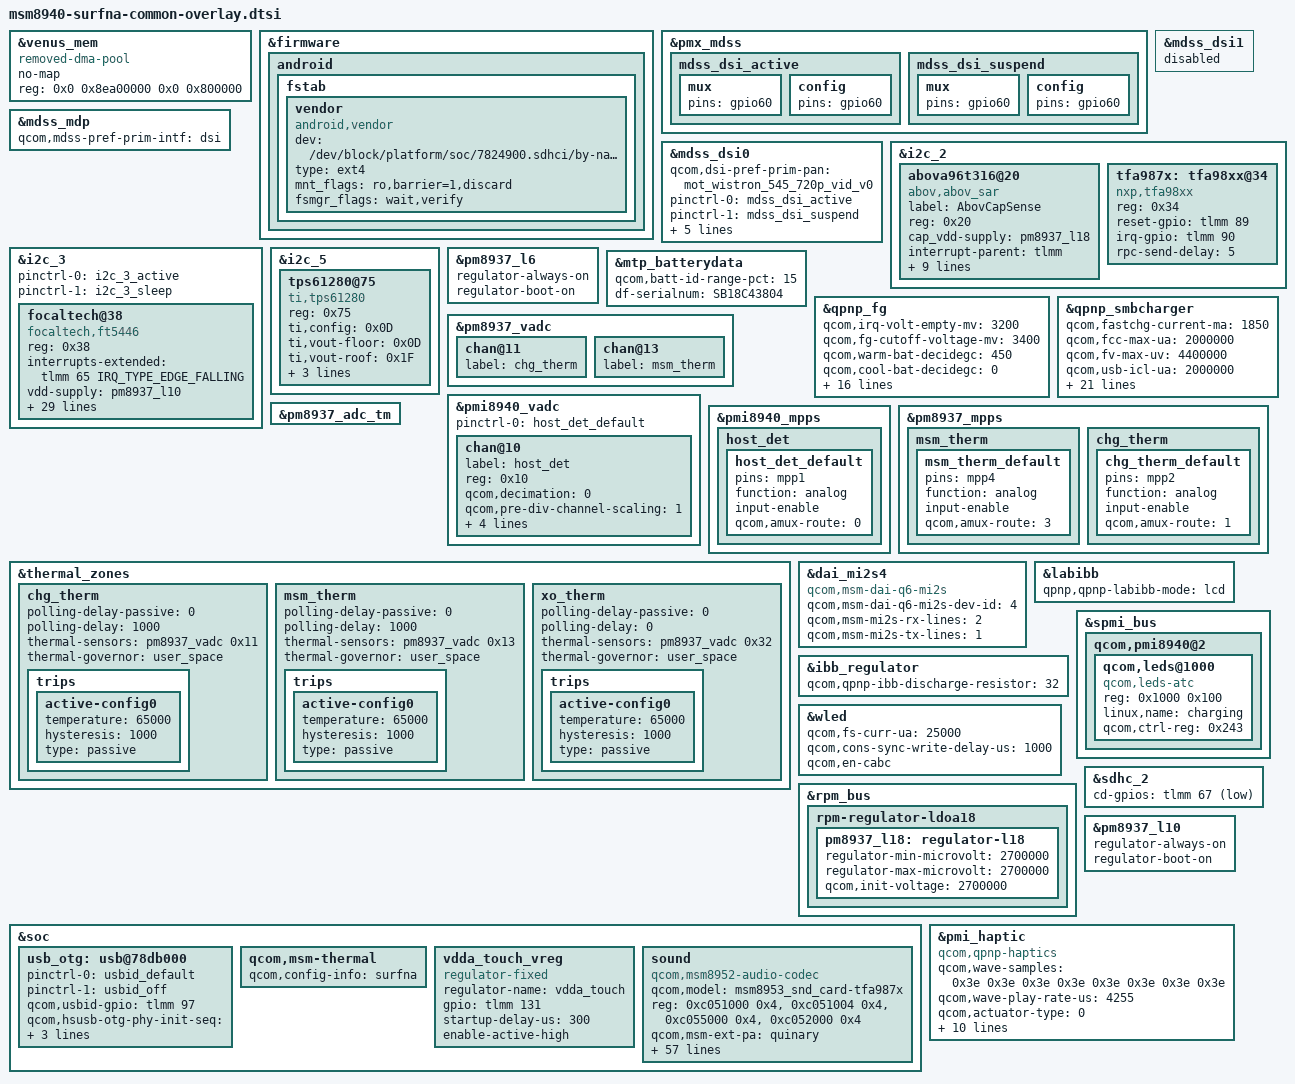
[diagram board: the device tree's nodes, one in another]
/* Copyright (c) 2018, Motorola Mobility Inc. All rights reserved.
 *
 * This program is free software; you can redistribute it and/or modify
 * it under the terms of the GNU General Public License version 2 and
 * only version 2 as published by the Free Software Foundation.
 *
 * This program is distributed in the hope that it will be useful,
 * but WITHOUT ANY WARRANTY; without even the implied warranty of
 * MERCHANTABILITY or FITNESS FOR A PARTICULAR PURPOSE.  See the
 * GNU General Public License for more details.
 */
#include "msm8940-moto-common-overlay.dtsi"
#include "msm8940-surfna-pinctrl-overlay.dtsi"
#include "msm8940-camera-sensor-surfna-overlay.dtsi"
#include "dsi-panel-mot-ofilm-545-720p-vid.dtsi"
#include "dsi-panel-mot-wistron_545_720p-video.dtsi"
#include "dsi-panel-mot-hlt-545-720p-vid.dtsi"
#include "dsi-panel-mot-djn_545_720p-video.dtsi"
#include <dt-bindings/interrupt-controller/irq.h>

&venus_mem {
	compatible = "removed-dma-pool";
	no-map;
	reg = <0x0 0x8ea00000 0x0 0x800000>;
};

&firmware {
	android {
		fstab {
			vendor {
				compatible = "android,vendor";
				dev = "/dev/block/platform/soc/7824900.sdhci/by-name/vendor";
				type = "ext4";
				mnt_flags = "ro,barrier=1,discard";
				fsmgr_flags = "wait,verify";
				status = "ok";
			};
		};
	};
};

&pmx_mdss {
	mdss_dsi_active {
		mux {
			pins = "gpio60";
		};

		config {
			pins = "gpio60";
		};
	};

	mdss_dsi_suspend {
		mux {
			pins = "gpio60";
		};

		config {
			pins = "gpio60";
		};
	};
};

&mdss_mdp {
	qcom,mdss-pref-prim-intf = "dsi";
};

&mdss_dsi0 {
	qcom,dsi-pref-prim-pan = <&mot_wistron_545_720p_vid_v0>;

	pinctrl-names = "mdss_default", "mdss_sleep";
	pinctrl-0 = <&mdss_dsi_active>;
	pinctrl-1 = <&mdss_dsi_suspend>;

	vddio_disp-supply = <&pm8937_l6>;
	vsp_disp-supply = <&lab_regulator>;
	vsn_disp-supply = <&ibb_regulator>;
	qcom,regulator-ldo-mode;
	qcom,platform-reset-gpio = <&tlmm 60 0>;
};

&mdss_dsi1 {
	status = "disabled";
};

&i2c_2 {
	status = "ok";
	abova96t316@20 {
		label = "AbovCapSense";
		compatible = "abov,abov_sar";
		reg = <0x20>;
		cap_vdd-supply = <&pm8937_l18>;
		//cap_svdd-supply = <&pm660_l14>;
		interrupt-parent = <&tlmm>;
		interrupts = <44 0x2008>;
		gpios = <&tlmm 44 0x2008>; /* IRQ */
		pinctrl-names = "default";
		pinctrl-0 = <&abov_int_default>;
		cap,use_channel = <0x0f>;
		cap,use_channel_top = <0x01>;
		cap,use_channel_bottom = <0x00>;
		cap,scan_period = <0x02>;
		reg_array_len = <3>;
		reg_array_val = <0x07 0x00 0x08 0x07 0xFB 0x01>;
	};

	/delete-node/ adv7533@39;
	/delete-node/ pericom-type-c@1d;

	tfa987x:tfa98xx@34 {
		compatible = "nxp,tfa98xx";
		reg = <0x34>;
		reset-gpio = <&tlmm 89 0>;
		irq-gpio = <&tlmm 90 0>;
		rpc-send-delay = <5>;
		status = "ok";
	};
};

&i2c_3 {
	status = "ok";
	/* clock-frequency = <400000>; */
	pinctrl-names = "i2c_active", "i2c_sleep";
	pinctrl-0 = <&i2c_3_active>;
	pinctrl-1 = <&i2c_3_sleep>;
	focaltech@38 {
		compatible = "focaltech,ft5446", "focaltech,mmi";
		reg = <0x38>;
		interrupts-extended = <&tlmm 65 IRQ_TYPE_EDGE_FALLING>;
                vdd-supply = <&pm8937_l10>;
		vcc_i2c-supply = <&pm8937_l5>;
		pinctrl-names = "pmx_ts_active","pmx_ts_suspend","pmx_ts_release";
		pinctrl-0 = <&ts_int_active &ts_reset_active>;
		pinctrl-1 = <&ts_int_suspend &ts_reset_suspend>;
		pinctrl-2 = <&ts_release>;
		focaltech,name = "ft5446";
		focaltech,family-id = <0x22>;
		focaltech,reset-gpio = <&tlmm 64 0x01>;
		focaltech,irq-gpio = <&tlmm 65 0x02>;
		focaltech,display-coords = <0 0 720 1440>;
		focaltech,max-touch-number = <10>;
		focaltech,no-force-update;
		focaltech,i2c-pull-up;
		focaltech,group-id = <1>;
		focaltech,hard-reset-delay-ms = <20>;
		focaltech,soft-reset-delay-ms = <200>;
		focaltech,num-max-touches = <10>;
		focaltech,fw-delay-aa-ms = <30>;
		focaltech,fw-delay-55-ms = <30>;
		focaltech,fw-upgrade-id1 = <0x79>;
		focaltech,fw-upgrade-id2 = <0x08>;
		focaltech,fw-delay-readid-ms = <10>;
		focaltech,fw-delay-era-flsh-ms = <2000>;
                focaltech,fw-update-mmi;
		focaltech,fw-auto-cal;
		focaltech,resume-in-workqueue;
		focaltech,ignore-id-check;
		touchpanel,use_dev_path;
		touchpanel,rst-gpio = <&tlmm 64 0x01>;
		touchpanel,irq-gpio = <&tlmm 65 0x02>;
	};

};

&i2c_5 {
	status = "ok";
	tps61280@75 {
		compatible = "ti,tps61280";
		status = "okay";
		reg = <0x75>;
		ti,config = <0x0D>;
		ti,vout-floor = <0x0D>;
		ti,vout-roof = <0x1F>;
		ti,ilim = <0x0F>;
		ti,en-gpio = <&tlmm 96 0x00>;
		pinctrl-names = "default";
		pinctrl-0 = <&tps61280_en_default>;
	};
};

&pm8937_l6 {
	regulator-always-on;
	regulator-boot-on;
};

&mtp_batterydata {
	qcom,batt-id-range-pct = <15>;
        df-serialnum = "SB18C43804";
        #include "batterydata-ke40-atl.dtsi"
        #include "batterydata-KE40_Sunwoda-4V4-2820mah.dtsi"
};


&qpnp_fg {
	qcom,irq-volt-empty-mv = <3200>;
	qcom,fg-cutoff-voltage-mv = <3400>;

	status = "okay";
	qcom,warm-bat-decidegc = <450>;
	qcom,cool-bat-decidegc = <0>;
	qcom,hot-bat-decidegc = <600>;
	qcom,cold-bat-decidegc = <(-200)>;
	/delete-property/ qcom,ext-sense-type; /* External Sense Resistor */
	qcom,thermal-coefficients = [DA 86 F0 50 08 3C];
	qcom,resume-soc = <99>;
	qcom,bcl-lm-threshold-ma = <126>;
	qcom,bcl-mh-threshold-ma = <400>;
	qcom,fg-iterm-ma = <150>;
        qcom,fg-chg-iterm-ma = <58>;
	qcom,fg-vbat-estimate-diff-mv = <1000>;
	qcom,fg-delta-soc = <1>;
	qcom,fg-max-soc = <100>;
	qcom,fg-min-soc = <0>;
	qcom,fg-cc-cv-threshold-mv = <4390>;
	qcom,battery-data = <&mtp_batterydata>;

	qcom,cl-vbat-est-thr-uv = <300000>;
	qcom,fg-force-restart-enable;
	/delete-property/ qcom,support_multi_coefficients;
};

&qpnp_smbcharger {
	qcom,fastchg-current-ma = <1850>;
	qcom,fcc-max-ua = <2000000>;
	qcom,fv-max-uv = <4400000>;
	qcom,usb-icl-ua = <2000000>;
	qcom,battery-data = <&mtp_batterydata>;
	qcom,chg-thermal-mitigation = <2000>,
                                <1850>,
				<1600>,
				<1200>,
				<1000>,
				<700>,
				<400>;
	qcom,enable-charging-limit;
	qcom,upper-limit-capacity = <75>;
	qcom,lower-limit-capacity = <60>;
	qcom,mmi-disable-hvdcp;
	dpdm-supply = <&usb_otg>;
	//qcom,chg-led-sw-controls;
	//qcom,chg-led-support;

	/delete-property/ qcom,dc-thermal-mitigation;
        qcom,parallel-charge-current-map = <2000 2000 0>,
                                        <1850 1850 0>,
					<1600 1600 0>,
					<1200 1200 0>,
					<1000 1000 0>,
					<700 700 0>,
					<400 400 0>;
	qcom,stepchg-voltage-mv = <4200>;
	qcom,stepchg-current-ma = <1850>;
	qcom,stepchg-taper-ma = <1850>;
	qcom,stepchg-iterm-ma = <58>;
	/delete-property/ qcom,enable-hvdcp-9v;
	qcom,weak-charger-check-enable;
	qcom,temp-warm-current-ma = <1455>;
	qcom,temp-cool-current-ma = <582>;
	qcom,temp-slightly-cool-current-ma = <582>;
	qcom,slightly-cool-temp-c = <15>;
        qcom,cold-temp-c = <(-14)>;
};

&pm8937_vadc {
	chan@11 {
		label = "chg_therm";
        };

	chan@13 {
		label = "msm_therm";
	};
};

&pmi8940_vadc {
        pinctrl-names = "default";
        pinctrl-0 = <&host_det_default>;

	chan@10 {
		label = "host_det";
		reg = <0x10>;
		qcom,decimation = <0>;
		qcom,pre-div-channel-scaling = <1>;
		qcom,calibration-type = "absolute";
		qcom,scale-function = <0>;
		qcom,hw-settle-time = <1>;
		qcom,fast-avg-setup = <2>;
	};
};

&pmi8940_mpps {
        host_det {
               host_det_default: host_det_default {
                     pins = "mpp1";
                     function = "analog";
                     input-enable;
                     qcom,amux-route = <0>;
               };
        };
};


&pm8937_adc_tm {
        #thermal-sensor-cells = <1>;
};


&thermal_zones {
        /delete-node/ pa-therm1-adc;
        /delete-node/ case-therm-adc;
	/delete-node/ xo-therm-adc;
	chg_therm {
		polling-delay-passive = <0>;
		polling-delay = <1000>;
		thermal-sensors = <&pm8937_vadc 0x11>;
		thermal-governor = "user_space";

		trips {
			active-config0 {
				temperature = <65000>;
				hysteresis = <1000>;
				type = "passive";
			};
		};
	};

	msm_therm {
		polling-delay-passive = <0>;
		polling-delay = <1000>;
		thermal-sensors = <&pm8937_vadc 0x13>;
		thermal-governor = "user_space";

		trips {
			active-config0 {
				temperature = <65000>;
				hysteresis = <1000>;
				type = "passive";
			};
		};
        };

	xo_therm {
		polling-delay-passive = <0>;
		polling-delay = <0>;
		thermal-sensors = <&pm8937_vadc 0x32>;
		thermal-governor = "user_space";

		trips {
			active-config0 {
			temperature = <65000>;
			hysteresis = <1000>;
			type = "passive";
			};
		};
	};
};

&pm8937_mpps {
        msm_therm {
               msm_therm_default: msm_therm_default {
               pins = "mpp4";
               function = "analog";
               input-enable;
               qcom,amux-route = <3>;
               };
        };

        chg_therm {
               chg_therm_default: chg_therm_default {
               pins = "mpp2";
               function = "analog";
               input-enable;
               qcom,amux-route = <1>;
               };
        };
};

&dai_mi2s4 {
	compatible = "qcom,msm-dai-q6-mi2s";
	qcom,msm-dai-q6-mi2s-dev-id = <4>;
	qcom,msm-mi2s-rx-lines = <2>;
	qcom,msm-mi2s-tx-lines = <1>;
};


/* display boost and inverting boost regulators */
&labibb {
	status = "ok";
	qpnp,qpnp-labibb-mode = "lcd";
};

&ibb_regulator {
	qcom,qpnp-ibb-discharge-resistor = <32>;
};

&wled {
	qcom,fs-curr-ua = <25000>;
	qcom,cons-sync-write-delay-us = <1000>;
	qcom,en-cabc;
};

&spmi_bus {
        qcom,pmi8940@2 {
                /delete-node/ qcom,leds@a100;
                qcom,leds@1000 {
                status = "ok";
                reg = <0x1000 0x100>;
                compatible = "qcom,leds-atc";
                linux,name = "charging";
                qcom,ctrl-reg = <0x243>;
                };
        };
};

&rpm_bus {
	rpm-regulator-ldoa18 {
		status = "okay";
		pm8937_l18: regulator-l18 {
			regulator-min-microvolt = <2700000>;
			regulator-max-microvolt = <2700000>;
			qcom,init-voltage = <2700000>;
			status = "okay";
		};
	};
};

&soc {
	usb_otg: usb@78db000 {
		pinctrl-names = "default","usbid-off";
		pinctrl-0 = <&usbid_default>;
		pinctrl-1 = <&usbid_off>;
		qcom,usbid-gpio = <&tlmm 97 0>;
		qcom,hsusb-otg-phy-init-seq =
			<0x77 0x80 0x26 0x81 0x3f 0x82 0x33 0x83 0xffffffff>;
		qcom,chg-dcp-icl = <1800>;
		extcon = <&qpnp_smbcharger>;
	};
	qcom,msm-thermal {
		qcom,config-info = "surfna";
	};

	vdda_touch_vreg: vdda_touch_vreg {
		compatible = "regulator-fixed";
		regulator-name = "vdda_touch";
		gpio = <&tlmm 131 0>;
		startup-delay-us = <300>;
		enable-active-high;
	};

	/delete-node/ hdmi_dba;
	/delete-node/ dai_hdmi;

	sound {
		status = "okay";
		compatible = "qcom,msm8952-audio-codec";
		qcom,model = "msm8953_snd_card-tfa987x";

		/delete-property/ qcom,cdc-us-euro-gpios;
		/delete-property/ asoc-wsa-codec-names;
		/delete-property/ asoc-wsa-codec-prefixes;
		/delete-property/ msm-vdd-wsa-switch-supply;
		/delete-property/ qcom,msm-vdd-wsa-switch-voltage;
		/delete-property/ qcom,msm-vdd-wsa-switch-current;
		/delete-property/ qcom,hdmi-dba-codec-rx;
		/delete-property/ qcom,msm-dai-q6-hdmi;

		reg = <0xc051000 0x4>,
			<0xc051004 0x4>,
			<0xc055000 0x4>,
			<0xc052000 0x4>;
		reg-names = "csr_gp_io_mux_mic_ctl",
			"csr_gp_io_mux_spkr_ctl",
			"csr_gp_io_lpaif_pri_pcm_pri_mode_muxsel",
			"csr_gp_io_mux_quin_ctl";

		qcom,msm-ext-pa = "quinary";
		nxp,have-tfa987x;
		qcom,msm-mclk-freq = <9600000>;
		qcom,msm-mbhc-hphl-swh = <1>;
		qcom,msm-mbhc-gnd-swh = <0>;
		qcom,msm-hs-micbias-type = "internal";
		qcom,msm-micbias1-ext-cap;
		qcom,msm-micbias2-ext-cap;

		qcom,audio-routing =
				"RX_BIAS", "MCLK",
				"SPK_RX_BIAS", "MCLK",
				"INT_LDO_H", "MCLK",
				"RX_I2S_CLK", "MCLK",
				"TX_I2S_CLK", "MCLK",
				"MIC BIAS External", "Handset Mic",
				"MIC BIAS Internal2", "Headset Mic",
				"MIC BIAS External", "Secondary Mic",
				"AMIC1", "MIC BIAS External",
				"AMIC2", "MIC BIAS Internal2",
				"AMIC3", "MIC BIAS External",
				"ADC1_IN", "ADC1_OUT",
				"ADC2_IN", "ADC2_OUT",
				"ADC3_IN", "ADC3_OUT",
				"PDM_IN_RX1", "PDM_OUT_RX1",
				"PDM_IN_RX2", "PDM_OUT_RX2",
				"PDM_IN_RX3", "PDM_OUT_RX3";

		qcom,pri-mi2s-gpios = <&cdc_pri_mi2s_gpios>;
		qcom,quin-mi2s-gpios = <&cdc_quin_mi2s_gpios>;

		asoc-platform = <&pcm0>, <&pcm1>, <&pcm2>, <&voip>, <&voice>,
				<&loopback>, <&compress>, <&hostless>,
				<&afe>, <&lsm>, <&routing>, <&pcm_noirq>;
		asoc-platform-names = "msm-pcm-dsp.0", "msm-pcm-dsp.1",
				"msm-pcm-dsp.2", "msm-voip-dsp",
				"msm-pcm-voice", "msm-pcm-loopback",
				"msm-compress-dsp", "msm-pcm-hostless",
				"msm-pcm-afe", "msm-lsm-client",
				"msm-pcm-routing", "msm-pcm-dsp-noirq";

		asoc-cpu = <&dai_pri_auxpcm>,
			<&dai_mi2s0>, <&dai_mi2s1>,
			<&dai_mi2s2>, <&dai_mi2s3>,
			<&dai_mi2s4>, <&dai_mi2s5>,
			<&sb_0_rx>, <&sb_0_tx>, <&sb_1_rx>, <&sb_1_tx>,
			<&sb_3_rx>, <&sb_3_tx>, <&sb_4_rx>, <&sb_4_tx>,
			<&bt_sco_rx>, <&bt_sco_tx>,
			<&int_fm_rx>, <&int_fm_tx>,
			<&afe_pcm_rx>, <&afe_pcm_tx>,
			<&afe_proxy_rx>, <&afe_proxy_tx>,
			<&incall_record_rx>, <&incall_record_tx>,
			<&incall_music_rx>, <&incall_music_2_rx>;
		asoc-cpu-names = "msm-dai-q6-auxpcm.1",
				"msm-dai-q6-mi2s.0", "msm-dai-q6-mi2s.1",
				"msm-dai-q6-mi2s.2", "msm-dai-q6-mi2s.3",
				"msm-dai-q6-mi2s.4", "msm-dai-q6-mi2s.6",
				"msm-dai-q6-dev.16384", "msmdai-q6-dev.16385",
				"msm-dai-q6-dev.16386", "msm-dai-q6-dev.16387",
				"msm-dai-q6-dev.16390", "msm-dai-q6-dev.16391",
				"msm-dai-q6-dev.16392", "msm-dai-q6-dev.16393",
				"msm-dai-q6-dev.12288", "msm-dai-q6-dev.12289",
				"msm-dai-q6-dev.12292", "msm-dai-q6-dev.12293",
				"msm-dai-q6-dev.224", "msm-dai-q6-dev.225",
				"msm-dai-q6-dev.241", "msm-dai-q6-dev.240",
				"msm-dai-q6-dev.32771", "msm-dai-q6-dev.32772",
				"msm-dai-q6-dev.32773", "msm-dai-q6-dev.32770";

		asoc-codec = <&stub_codec>, <&msm_digital_codec>,
				<&pmic_analog_codec>;
		asoc-codec-names = "msm-stub-codec.1", "msm-dig-codec",
					"analog-codec";
	};
};

&sdhc_2 {
	cd-gpios = <&tlmm 67 0x1>;
};


&pm8937_l10 {
	regulator-always-on;
	regulator-boot-on;
};

&pmi_haptic {
	compatible = "qcom,qpnp-haptics";
	interrupt-names = "hap-sc-irq", "hap-play-irq";
	qcom,wave-samples = <0x3e 0x3e 0x3e 0x3e 0x3e
                        0x3e 0x3e 0x3e>;
	qcom,wave-play-rate-us = <4255>;
	qcom,actuator-type = <0>; //LRA
	qcom,wave-shape = "sine";
	qcom,vmax-mv = <2450>;
        qcom,max-play-time-ms = <30000>;
	qcom,brake-pattern = <0x3 0x3 0x3 0x3>;
	qcom,en-brake;
	qcom,lra-auto-res-mode="qwd";
	qcom,lra-high-z="opt1";
	qcom,lra-res-cal-period = <4>;
	qcom,correct-lra-drive-freq;
	qcom,misc-trim-error-rc19p2-clk-reg-present;
};
